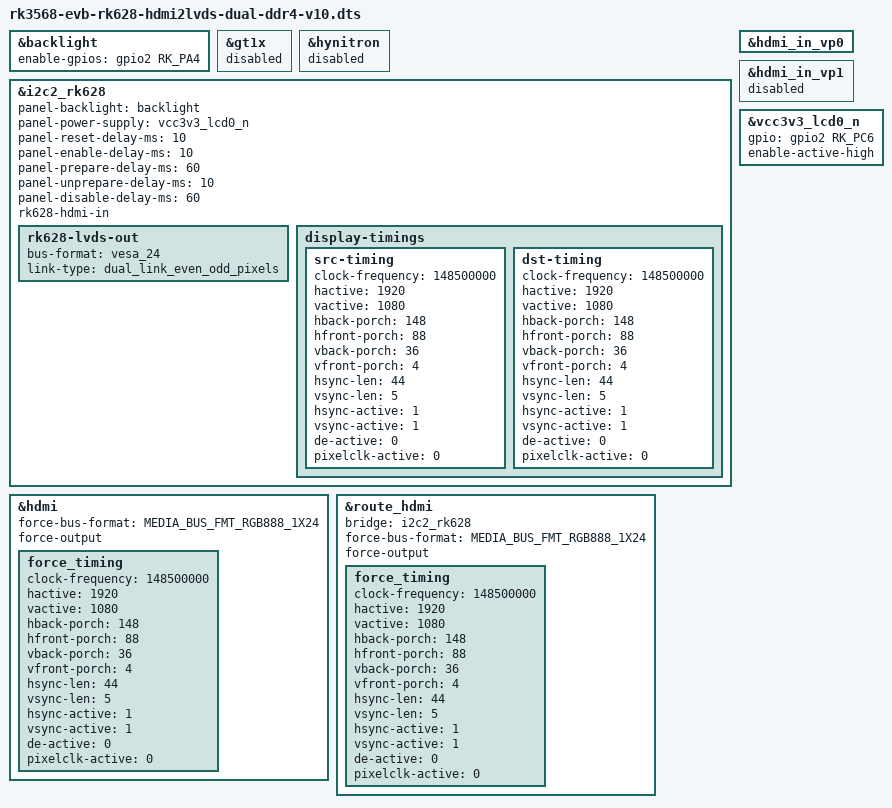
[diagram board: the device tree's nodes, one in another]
// SPDX-License-Identifier: (GPL-2.0+ OR MIT)
/*
 * Copyright (c) 2020 Rockchip Electronics Co., Ltd.
 *
 */

#include <dt-bindings/display/media-bus-format.h>
#include "rk3568-evb-rk628-ddr4-v10.dtsi"
#include "rk3568-android.dtsi"

&backlight {
	enable-gpios = <&gpio2 RK_PA4 GPIO_ACTIVE_HIGH>;
};

&gt1x {
	status = "disabled";
};

&hynitron {
	status = "disabled";
};

&i2c2_rk628 {
		panel-backlight = <&backlight>;
		panel-power-supply = <&vcc3v3_lcd0_n>;
		panel-reset-delay-ms = <10>;
		panel-enable-delay-ms = <10>;
		panel-prepare-delay-ms = <60>;
		panel-unprepare-delay-ms = <10>;
		panel-disable-delay-ms = <60>;

		rk628-hdmi-in;
		rk628-lvds-out {
			/* "jeida_18","vesa_24","vesa_18" */
			bus-format = "vesa_24";

			/* "dual_link_odd_even_pixels"
			 * "dual_link_even_odd_pixels"
			 * "dual_link_left_right_pixels"
			 * "dual_link_right_left_pixels"
			 */
			link-type = "dual_link_even_odd_pixels";
			status = "okay";
		};

		display-timings {
			src-timing {
				clock-frequency = <148500000>;
				hactive = <1920>;
				vactive = <1080>;
				hback-porch = <148>;
				hfront-porch = <88>;
				vback-porch = <36>;
				vfront-porch = <4>;
				hsync-len = <44>;
				vsync-len = <5>;
				hsync-active = <1>;
				vsync-active = <1>;
				de-active = <0>;
				pixelclk-active = <0>;
			};

			dst-timing {
				clock-frequency = <148500000>;
				hactive = <1920>;
				vactive = <1080>;
				hback-porch = <148>;
				hfront-porch = <88>;
				vback-porch = <36>;
				vfront-porch = <4>;
				hsync-len = <44>;
				vsync-len = <5>;
				hsync-active = <1>;
				vsync-active = <1>;
				de-active = <0>;
				pixelclk-active = <0>;
			};
	    };
};

&hdmi {
	status = "okay";
	force-bus-format = <MEDIA_BUS_FMT_RGB888_1X24>;
	force-output;
	force_timing{
		clock-frequency = <148500000>;
		hactive = <1920>;
		vactive = <1080>;
		hback-porch = <148>;
		hfront-porch = <88>;
		vback-porch = <36>;
		vfront-porch = <4>;
		hsync-len = <44>;
		vsync-len = <5>;
		hsync-active = <1>;
		vsync-active = <1>;
		de-active = <0>;
		pixelclk-active = <0>;
	};
};

&hdmi_in_vp0 {
	status = "okay";
};

&hdmi_in_vp1 {
	status = "disabled";
};

&route_hdmi {
	status = "okay";

	bridge = <&i2c2_rk628>;
	force-bus-format = <MEDIA_BUS_FMT_RGB888_1X24>;
	force-output;
	force_timing{
		clock-frequency = <148500000>;
		hactive = <1920>;
		vactive = <1080>;
		hback-porch = <148>;
		hfront-porch = <88>;
		vback-porch = <36>;
		vfront-porch = <4>;
		hsync-len = <44>;
		vsync-len = <5>;
		hsync-active = <1>;
		vsync-active = <1>;
		de-active = <0>;
		pixelclk-active = <0>;
	};
};

&vcc3v3_lcd0_n {
	gpio = <&gpio2 RK_PC6 GPIO_ACTIVE_HIGH>;
	enable-active-high;
};
